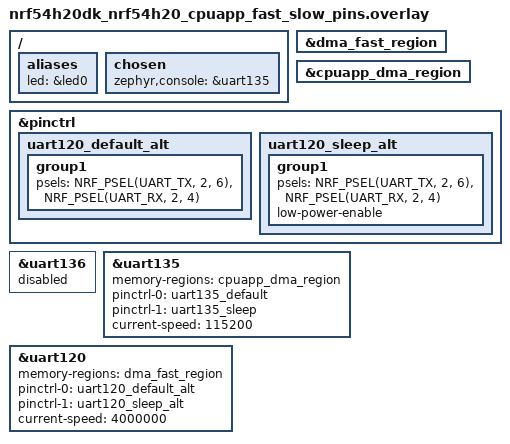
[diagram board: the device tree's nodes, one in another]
/*
 * Copyright (c) 2024 Nordic Semiconductor ASA
 *
 * SPDX-License-Identifier: LicenseRef-Nordic-5-Clause
 */

/*
 * To execute this test case the following loopback
 * is required: P2.04 <--> P2.06
 * Note: Console UART is connected to P1 (if02)
 */

/ {
	aliases {
		led = &led0;
		/delete-property/ led1;
	};

	chosen {
		zephyr,console = &uart135;
	};
};

/delete-node/ &led1;

&dma_fast_region {
	status = "okay";
};

&cpuapp_dma_region {
	status = "okay";
};

&pinctrl {
	uart120_default_alt: uart120_default_alt {
		group1 {
			psels = <NRF_PSEL(UART_TX, 2, 6)>,
				<NRF_PSEL(UART_RX, 2, 4)>;
		};
	};

	uart120_sleep_alt: uart120_sleep_alt {
		group1 {
			psels = <NRF_PSEL(UART_TX, 2, 6)>,
				<NRF_PSEL(UART_RX, 2, 4)>;
			low-power-enable;
		};
	};
};

&uart136 {
	status = "disabled";
	/delete-property/ memory-regions;
};

&uart135 {
	status = "okay";
	memory-regions = <&cpuapp_dma_region>;
	pinctrl-0 = <&uart135_default>;
	pinctrl-1 = <&uart135_sleep>;
	pinctrl-names = "default", "sleep";
	current-speed = <115200>;
	/delete-property/ hw-flow-control;
};

dut: &uart120 {
	status = "okay";
	memory-regions = <&dma_fast_region>;
	pinctrl-0 = <&uart120_default_alt>;
	pinctrl-1 = <&uart120_sleep_alt>;
	pinctrl-names = "default", "sleep";
	current-speed = <4000000>;
	/delete-property/ hw-flow-control;
};
